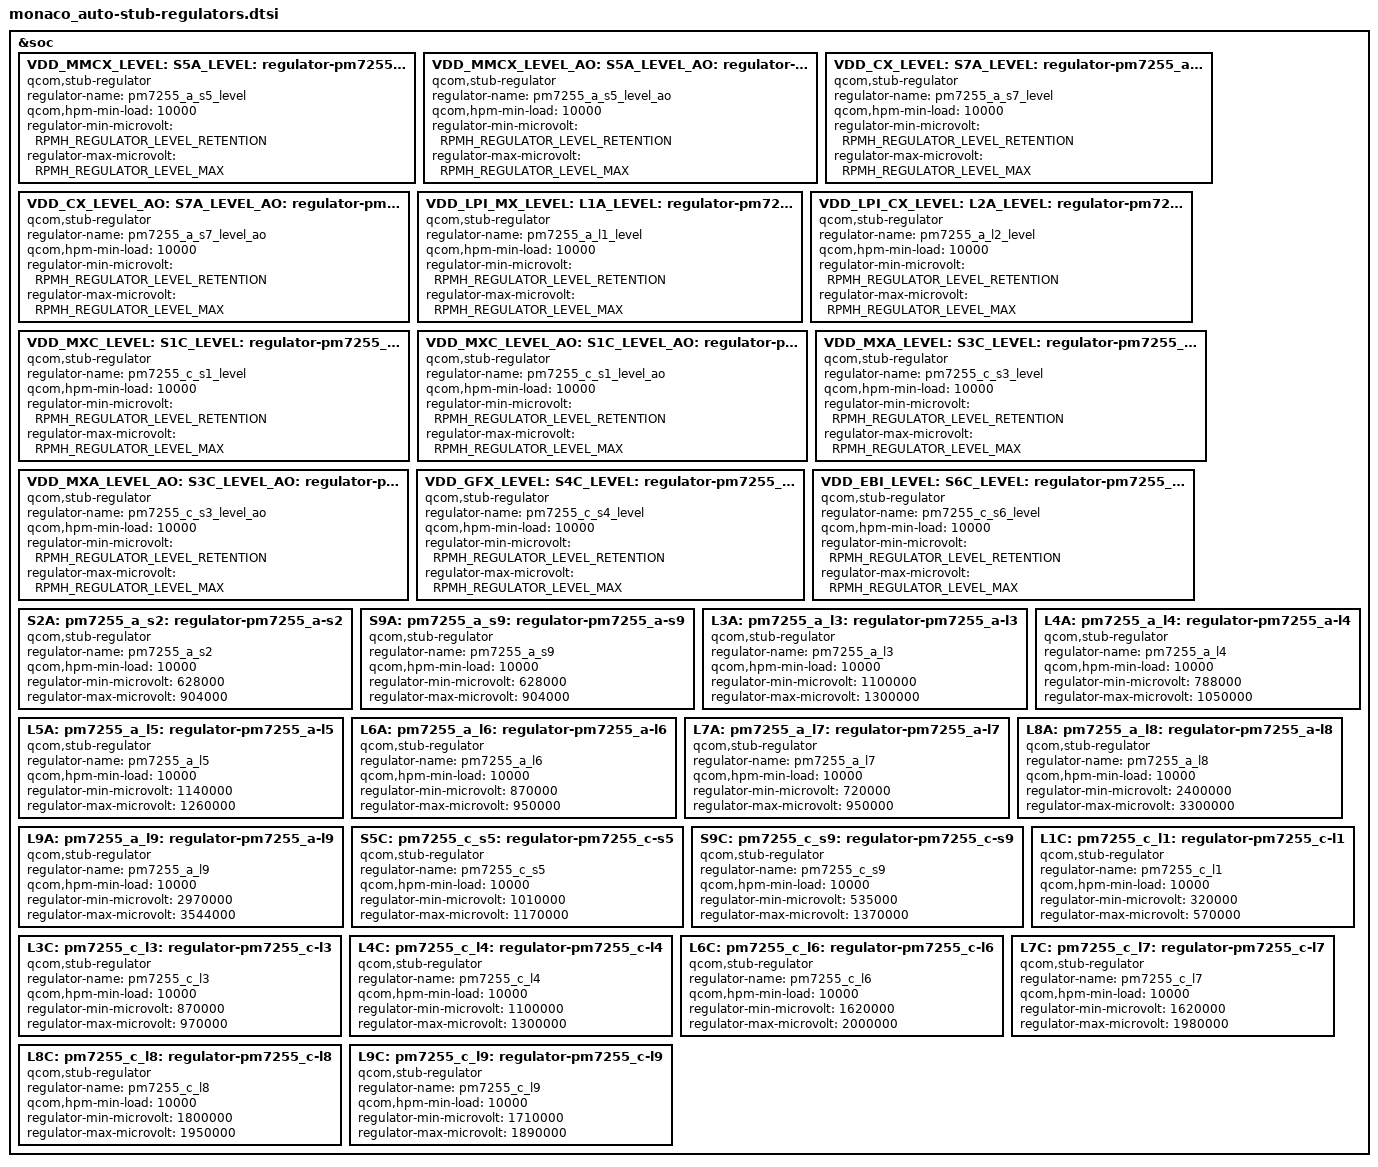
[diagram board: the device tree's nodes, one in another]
#include <dt-bindings/regulator/qcom,rpmh-regulator-levels.h>

&soc {

		VDD_MMCX_LEVEL:
		S5A_LEVEL:
		pm7255_a_s5_level: regulator-pm7255_a-s5-level {
			compatible = "qcom,stub-regulator";
			regulator-name = "pm7255_a_s5_level";
			qcom,hpm-min-load = <10000>;
			regulator-min-microvolt =
				<RPMH_REGULATOR_LEVEL_RETENTION>;
			regulator-max-microvolt =
				<RPMH_REGULATOR_LEVEL_MAX>;
		};

		VDD_MMCX_LEVEL_AO:
		S5A_LEVEL_AO:
		pm7255_a_s5_level_ao: regulator-pm7255_a-s5-level-ao {
			compatible = "qcom,stub-regulator";
			regulator-name = "pm7255_a_s5_level_ao";
			qcom,hpm-min-load = <10000>;
			regulator-min-microvolt =
				<RPMH_REGULATOR_LEVEL_RETENTION>;
			regulator-max-microvolt =
				<RPMH_REGULATOR_LEVEL_MAX>;
		};

		VDD_CX_LEVEL:
		S7A_LEVEL:
		pm7255_a_s7_level: regulator-pm7255_a-s7-level {
			compatible = "qcom,stub-regulator";
			regulator-name = "pm7255_a_s7_level";
			qcom,hpm-min-load = <10000>;
			regulator-min-microvolt =
				<RPMH_REGULATOR_LEVEL_RETENTION>;
			regulator-max-microvolt =
				<RPMH_REGULATOR_LEVEL_MAX>;
		};

		VDD_CX_LEVEL_AO:
		S7A_LEVEL_AO:
		pm7255_a_s7_level_ao: regulator-pm7255_a-s7-level-ao {
			compatible = "qcom,stub-regulator";
			regulator-name = "pm7255_a_s7_level_ao";
			qcom,hpm-min-load = <10000>;
			regulator-min-microvolt =
				<RPMH_REGULATOR_LEVEL_RETENTION>;
			regulator-max-microvolt =
				<RPMH_REGULATOR_LEVEL_MAX>;
		};

		VDD_LPI_MX_LEVEL:
		L1A_LEVEL:
		pm7255_a_l1_level: regulator-pm7255_a-l1-level {
			compatible = "qcom,stub-regulator";
			regulator-name = "pm7255_a_l1_level";
			qcom,hpm-min-load = <10000>;
			regulator-min-microvolt =
				<RPMH_REGULATOR_LEVEL_RETENTION>;
			regulator-max-microvolt =
				<RPMH_REGULATOR_LEVEL_MAX>;
		};

		VDD_LPI_CX_LEVEL:
		L2A_LEVEL:
		pm7255_a_l2_level: regulator-pm7255_a-l2-level {
			compatible = "qcom,stub-regulator";
			regulator-name = "pm7255_a_l2_level";
			qcom,hpm-min-load = <10000>;
			regulator-min-microvolt =
				<RPMH_REGULATOR_LEVEL_RETENTION>;
			regulator-max-microvolt =
				<RPMH_REGULATOR_LEVEL_MAX>;
		};

		VDD_MXC_LEVEL:
		S1C_LEVEL:
		pm7255_c_s1_level: regulator-pm7255_c-s1-level {
			compatible = "qcom,stub-regulator";
			regulator-name = "pm7255_c_s1_level";
			qcom,hpm-min-load = <10000>;
			regulator-min-microvolt =
				<RPMH_REGULATOR_LEVEL_RETENTION>;
			regulator-max-microvolt =
				<RPMH_REGULATOR_LEVEL_MAX>;
		};

		VDD_MXC_LEVEL_AO:
		S1C_LEVEL_AO:
		pm7255_c_s1_level_ao: regulator-pm7255_c-s1-level-ao {
			compatible = "qcom,stub-regulator";
			regulator-name = "pm7255_c_s1_level_ao";
			qcom,hpm-min-load = <10000>;
			regulator-min-microvolt =
				<RPMH_REGULATOR_LEVEL_RETENTION>;
			regulator-max-microvolt =
				<RPMH_REGULATOR_LEVEL_MAX>;
		};

		VDD_MXA_LEVEL:
		S3C_LEVEL:
		pm7255_c_s3_level: regulator-pm7255_c-s3-level {
			compatible = "qcom,stub-regulator";
			regulator-name = "pm7255_c_s3_level";
			qcom,hpm-min-load = <10000>;
			regulator-min-microvolt =
				<RPMH_REGULATOR_LEVEL_RETENTION>;
			regulator-max-microvolt =
				<RPMH_REGULATOR_LEVEL_MAX>;
		};

		VDD_MXA_LEVEL_AO:
		S3C_LEVEL_AO:
		pm7255_c_s3_level_ao: regulator-pm7255_c-s3-level-ao {
			compatible = "qcom,stub-regulator";
			regulator-name = "pm7255_c_s3_level_ao";
			qcom,hpm-min-load = <10000>;
			regulator-min-microvolt =
				<RPMH_REGULATOR_LEVEL_RETENTION>;
			regulator-max-microvolt =
				<RPMH_REGULATOR_LEVEL_MAX>;
		};

		VDD_GFX_LEVEL:
		S4C_LEVEL:
		pm7255_c_s4_level: regulator-pm7255_c-s4-level {
			compatible = "qcom,stub-regulator";
			regulator-name = "pm7255_c_s4_level";
			qcom,hpm-min-load = <10000>;
			regulator-min-microvolt =
				<RPMH_REGULATOR_LEVEL_RETENTION>;
			regulator-max-microvolt =
				<RPMH_REGULATOR_LEVEL_MAX>;
		};

		VDD_EBI_LEVEL:
		S6C_LEVEL:
		pm7255_c_s6_level: regulator-pm7255_c-s6-level {
			compatible = "qcom,stub-regulator";
			regulator-name = "pm7255_c_s6_level";
			qcom,hpm-min-load = <10000>;
			regulator-min-microvolt =
				<RPMH_REGULATOR_LEVEL_RETENTION>;
			regulator-max-microvolt =
				<RPMH_REGULATOR_LEVEL_MAX>;
		};

		S2A:
		pm7255_a_s2: regulator-pm7255_a-s2 {
			compatible = "qcom,stub-regulator";
			regulator-name = "pm7255_a_s2";
			qcom,hpm-min-load = <10000>;
			regulator-min-microvolt = <628000>;
			regulator-max-microvolt = <904000>;
		};

		S9A:
		pm7255_a_s9: regulator-pm7255_a-s9 {
			compatible = "qcom,stub-regulator";
			regulator-name = "pm7255_a_s9";
			qcom,hpm-min-load = <10000>;
			regulator-min-microvolt = <628000>;
			regulator-max-microvolt = <904000>;
		};

		L3A:
		pm7255_a_l3: regulator-pm7255_a-l3 {
			compatible = "qcom,stub-regulator";
			regulator-name = "pm7255_a_l3";
			qcom,hpm-min-load = <10000>;
			regulator-min-microvolt = <1100000>;
			regulator-max-microvolt = <1300000>;
		};

		L4A:
		pm7255_a_l4: regulator-pm7255_a-l4 {
			compatible = "qcom,stub-regulator";
			regulator-name = "pm7255_a_l4";
			qcom,hpm-min-load = <10000>;
			regulator-min-microvolt = <788000>;
			regulator-max-microvolt = <1050000>;
		};

		L5A:
		pm7255_a_l5: regulator-pm7255_a-l5 {
			compatible = "qcom,stub-regulator";
			regulator-name = "pm7255_a_l5";
			qcom,hpm-min-load = <10000>;
			regulator-min-microvolt = <1140000>;
			regulator-max-microvolt = <1260000>;
		};

		L6A:
		pm7255_a_l6: regulator-pm7255_a-l6 {
			compatible = "qcom,stub-regulator";
			regulator-name = "pm7255_a_l6";
			qcom,hpm-min-load = <10000>;
			regulator-min-microvolt = <870000>;
			regulator-max-microvolt = <950000>;
		};

		L7A:
		pm7255_a_l7: regulator-pm7255_a-l7 {
			compatible = "qcom,stub-regulator";
			regulator-name = "pm7255_a_l7";
			qcom,hpm-min-load = <10000>;
			regulator-min-microvolt = <720000>;
			regulator-max-microvolt = <950000>;
		};

		L8A:
		pm7255_a_l8: regulator-pm7255_a-l8 {
			compatible = "qcom,stub-regulator";
			regulator-name = "pm7255_a_l8";
			qcom,hpm-min-load = <10000>;
			regulator-min-microvolt = <2400000>;
			regulator-max-microvolt = <3300000>;
		};

		L9A:
		pm7255_a_l9: regulator-pm7255_a-l9 {
			compatible = "qcom,stub-regulator";
			regulator-name = "pm7255_a_l9";
			qcom,hpm-min-load = <10000>;
			regulator-min-microvolt = <2970000>;
			regulator-max-microvolt = <3544000>;
		};

		S5C:
		pm7255_c_s5: regulator-pm7255_c-s5 {
			compatible = "qcom,stub-regulator";
			regulator-name = "pm7255_c_s5";
			qcom,hpm-min-load = <10000>;
			regulator-min-microvolt = <1010000>;
			regulator-max-microvolt = <1170000>;
		};

		S9C:
		pm7255_c_s9: regulator-pm7255_c-s9 {
			compatible = "qcom,stub-regulator";
			regulator-name = "pm7255_c_s9";
			qcom,hpm-min-load = <10000>;
			regulator-min-microvolt = <535000>;
			regulator-max-microvolt = <1370000>;
		};

		L1C:
		pm7255_c_l1: regulator-pm7255_c-l1 {
			compatible = "qcom,stub-regulator";
			regulator-name = "pm7255_c_l1";
			qcom,hpm-min-load = <10000>;
			regulator-min-microvolt = <320000>;
			regulator-max-microvolt = <570000>;
		};

		L3C:
		pm7255_c_l3: regulator-pm7255_c-l3 {
			compatible = "qcom,stub-regulator";
			regulator-name = "pm7255_c_l3";
			qcom,hpm-min-load = <10000>;
			regulator-min-microvolt = <870000>;
			regulator-max-microvolt = <970000>;
		};

		L4C:
		pm7255_c_l4: regulator-pm7255_c-l4 {
			compatible = "qcom,stub-regulator";
			regulator-name = "pm7255_c_l4";
			qcom,hpm-min-load = <10000>;
			regulator-min-microvolt = <1100000>;
			regulator-max-microvolt = <1300000>;
		};

		L6C:
		pm7255_c_l6: regulator-pm7255_c-l6 {
			compatible = "qcom,stub-regulator";
			regulator-name = "pm7255_c_l6";
			qcom,hpm-min-load = <10000>;
			regulator-min-microvolt = <1620000>;
			regulator-max-microvolt = <2000000>;
		};

		L7C:
		pm7255_c_l7: regulator-pm7255_c-l7 {
			compatible = "qcom,stub-regulator";
			regulator-name = "pm7255_c_l7";
			qcom,hpm-min-load = <10000>;
			regulator-min-microvolt = <1620000>;
			regulator-max-microvolt = <1980000>;
		};

		L8C:
		pm7255_c_l8: regulator-pm7255_c-l8 {
			compatible = "qcom,stub-regulator";
			regulator-name = "pm7255_c_l8";
			qcom,hpm-min-load = <10000>;
			regulator-min-microvolt = <1800000>;
			regulator-max-microvolt = <1950000>;
		};

		L9C:
		pm7255_c_l9: regulator-pm7255_c-l9 {
			compatible = "qcom,stub-regulator";
			regulator-name = "pm7255_c_l9";
			qcom,hpm-min-load = <10000>;
			regulator-min-microvolt = <1710000>;
			regulator-max-microvolt = <1890000>;
		};
};

